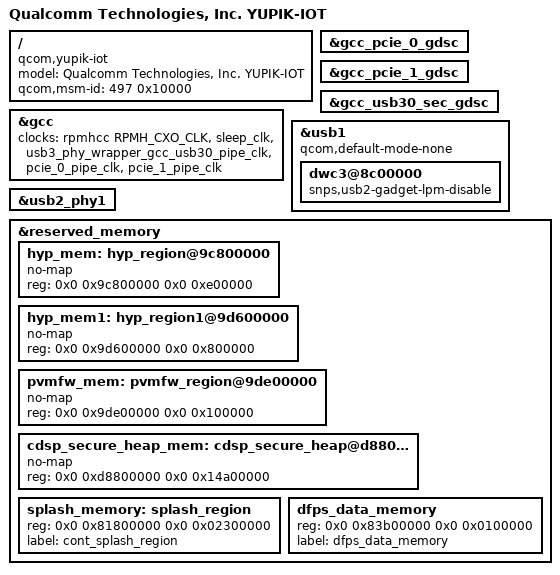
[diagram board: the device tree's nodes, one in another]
// SPDX-License-Identifier: BSD-3-Clause
/*
 * Copyright (c) Qualcomm Technologies, Inc. and/or its subsidiaries.
 */

#include "yupik.dtsi"

/ {
	model = "Qualcomm Technologies, Inc. YUPIK-IOT";
	compatible = "qcom,yupik-iot";
	qcom,msm-id = <497 0x10000>;
};

&gcc {
	clocks = <&rpmhcc RPMH_CXO_CLK>, <&sleep_clk>,
		<&usb3_phy_wrapper_gcc_usb30_pipe_clk>,
		<&pcie_0_pipe_clk>, <&pcie_1_pipe_clk>;
	clock-names = "bi_tcxo", "sleep_clk",
		"usb3_phy_wrapper_gcc_usb30_pipe_clk",
		"pcie_0_pipe_clk", "pcie_1_pipe_clk";

	/delete-property/ protected-clocks;
};

&gcc_pcie_0_gdsc {
	status = "ok";
};

&gcc_pcie_1_gdsc {
	status = "ok";
};

&gcc_usb30_sec_gdsc {
	status = "ok";
};

&usb1 {
	qcom,default-mode-none;
	status = "ok";
	dwc3@8c00000 {
		snps,usb2-gadget-lpm-disable;
	};
};

&usb2_phy1 {
	status = "ok";
};

/delete-node/ &hyp_mem;
/delete-node/ &cdsp_secure_heap_mem;
/delete-node/ &splash_memory;
/delete-node/ &dfps_data_memory;

&reserved_memory {
	hyp_mem: hyp_region@9c800000 {
		no-map;
		reg = <0x0 0x9c800000 0x0 0xe00000>;
	};

	hyp_mem1: hyp_region1@9d600000 {
		no-map;
		reg = <0x0 0x9d600000 0x0 0x800000>;
	};

	pvmfw_mem: pvmfw_region@9de00000 {
		 no-map;
		 reg = <0x0 0x9de00000 0x0 0x100000>;
	};

	cdsp_secure_heap_mem: cdsp_secure_heap@d8800000 {
		no-map;
		reg = <0x0 0xd8800000 0x0 0x14a00000>;
	};

	splash_memory: splash_region {
		reg = <0x0 0x81800000 0x0 0x02300000>;
		label = "cont_splash_region";
	};

	dfps_data_memory: dfps_data_memory {
		reg = <0x0 0x83b00000 0x0 0x0100000>;
		label = "dfps_data_memory";
	};
};
